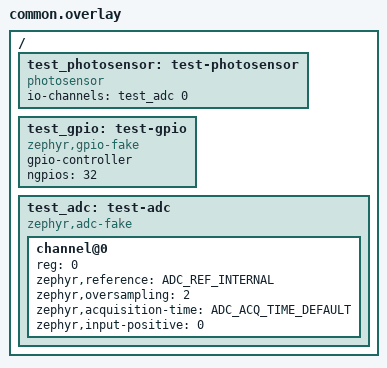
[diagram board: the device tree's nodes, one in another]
/*
 * Copyright (c) 2026 Nordic Semiconductor ASA
 *
 * SPDX-License-Identifier: Apache-2.0
 */

#include <zephyr/dt-bindings/gpio/gpio.h>
#include <zephyr/dt-bindings/adc/adc.h>

/ {
	test_photosensor: test-photosensor {
		compatible = "photosensor";
		io-channels = <&test_adc 0>;
	};

	test_gpio: test-gpio {
		compatible = "zephyr,gpio-fake";
		gpio-controller;
		#gpio-cells = <0x2>;
		ngpios = <32>;
	};

	test_adc: test-adc {
		compatible = "zephyr,adc-fake";
		#address-cells = <1>;
		#size-cells = <0>;
		#io-channel-cells = <1>;

		channel@0 {
			reg = <0>;
			zephyr,reference = "ADC_REF_INTERNAL";
			zephyr,oversampling = <2>;
			zephyr,acquisition-time = <ADC_ACQ_TIME_DEFAULT>;
			zephyr,input-positive = <0>;
		};
	};
};
